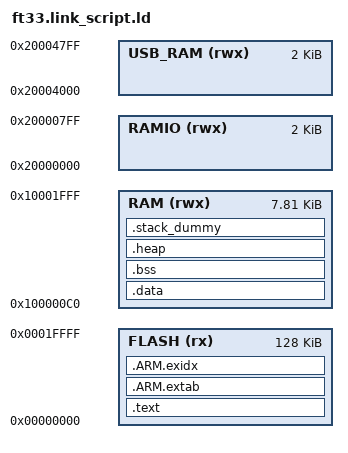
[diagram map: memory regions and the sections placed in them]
MEMORY
{
  FLASH (rx) : ORIGIN = 0x00000000, LENGTH = 128K
  RAM (rwx) : ORIGIN = 0x100000C0, LENGTH = 0x1F40
  RAMIO (rwx) : ORIGIN = 0x20000000, LENGTH = 0x800
  USB_RAM (rwx): ORIGIN = 0x20004000, LENGTH = 0x800
}
ENTRY(Reset_Handler)
SECTIONS
{
    .text :
    {
        KEEP(*(.isr_vector))
        *(.text.Reset_Handler)
        . = 0x00000200;
        *(.text*)
        KEEP(*(.init))
        KEEP(*(.fini))
        *crtbegin.o(.ctors)
        *crtbegin?.o(.ctors)
        *(EXCLUDE_FILE(*crtend?.o *crtend.o) .ctors)
        *(SORT(.ctors.*))
        *(.ctors)
        *crtbegin.o(.dtors)
        *crtbegin?.o(.dtors)
        *(EXCLUDE_FILE(*crtend?.o *crtend.o) .dtors)
        *(SORT(.dtors.*))
        *(.dtors)
        *(.rodata*)
        KEEP(*(.eh_frame*))
    } > FLASH
    .ARM.extab :
    {
        *(.ARM.extab* .gnu.linkonce.armextab.*)
    } > FLASH
    __exidx_start = .;
    .ARM.exidx :
    {
        *(.ARM.exidx* .gnu.linkonce.armexidx.*)
    } > FLASH
    __exidx_end = .;
    __etext = .;
    .data : AT (__etext)
    {
        __data_start__ = .;
        *(vtable)
        *(.data*)
        . = ALIGN(4);
        PROVIDE (__preinit_array_start = .);
        KEEP(*(.preinit_array))
        PROVIDE (__preinit_array_end = .);
        . = ALIGN(4);
        PROVIDE (__init_array_start = .);
        KEEP(*(SORT(.init_array.*)))
        KEEP(*(.init_array))
        PROVIDE (__init_array_end = .);
        . = ALIGN(4);
        PROVIDE (__fini_array_start = .);
        KEEP(*(SORT(.fini_array.*)))
        KEEP(*(.fini_array))
        PROVIDE (__fini_array_end = .);
        . = ALIGN(4);
        __data_end__ = .;
    } > RAM
    .bss :
    {
        __bss_start__ = .;
        *(.bss*)
        *(COMMON)
        __bss_end__ = .;
    } > RAM
    .heap :
    {
        __end__ = .;
        end = __end__;
        *(.heap*)
        __HeapLimit = .;
    } > RAM
    .stack_dummy :
    {
        *(.stack)
    } > RAM
    __StackTop = ORIGIN(RAM) + LENGTH(RAM);
    __StackLimit = __StackTop - SIZEOF(.stack_dummy);
    PROVIDE(__stack = __StackTop);
    ASSERT(__StackLimit >= __HeapLimit, "region RAM overflowed with stack")
}
